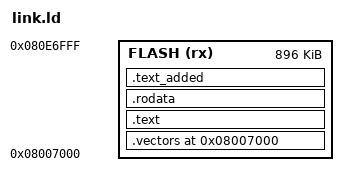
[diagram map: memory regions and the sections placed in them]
/* link.ld - memory layout of the FNIRSI 2C53T application.
 * Below 0x08007000 are the bootloader and the settings / calibration page at 0x08006000; this image
 * starts at 0x08007000 and never covers them.  RAM addresses are absolute in the code
 * (0x20000000..0x20036F8F: initial values 0x20000000..0x2000123F copied from src/ram_init.s at reset, the rest zeroed; stack top 0x20036F90).
 * Layout: vector table at 0x08007000 (the only fixed address), then the original functions in their
 * original order, then the data of src/rodata.s, then code added by this rewrite; each section follows
 * the one before it.  Code and data refer to each other only through symbols, so they may move.  The
 * address comments of the KEEP lines name each unit's address in V1.2.0's layout, not a required one.
 * FLASH ends at APP_END 0x080E7000: above it are the record pages and the bootloader slots of the
 * two-part bootloader (common/layout.inc); the flash is 1024 KB (word 0x00000400 at 0x1FFFF7E0, SYSINFO). */
MEMORY
{
  FLASH (rx) : ORIGIN = 0x08007000, LENGTH = 0x080E7000 - 0x08007000   /* APP_END, common/layout.inc */
}
ENTRY(Reset_Handler)
SECTIONS
{
  .vectors 0x08007000 : { KEEP(*(.vectors)) } > FLASH            /* fixed: the bootloader starts the application here */
  .text :                                                          /* right after the vector table */
  {
    KEEP(*(.text.fn_08007184))                                 /* 0x08007184 */
    KEEP(*(.text.__scatterload))                               /* 0x0800718c */
    KEEP(*(.text.unpack_token_stream))                         /* 0x080071c0 */
    KEEP(*(.text.zero_fill_words))                             /* 0x0800721c */
    KEEP(*(.text.format_one_conversion))                       /* 0x08007238 */
    KEEP(*(.text.fn_080072c8))                                 /* 0x080072c8 */
    KEEP(*(.text.nop_return_080072ec))                         /* 0x080072ec */
    KEEP(*(.text.fn_080072f0))                                 /* 0x080072f0 */
    KEEP(*(.text.fn_08007302))                                 /* 0x08007302 */
    KEEP(*(.text.Reset_Handler))                               /* 0x08007310 */
    KEEP(*(.text.halt_loop_08007332))                          /* 0x08007332 */
    KEEP(*(.text.halt_loop_08007334))                          /* 0x08007334 */
    KEEP(*(.text.halt_loop_08007336))                          /* 0x08007336 */
    KEEP(*(.text.halt_loop_08007338))                          /* 0x08007338 */
    KEEP(*(.text.halt_loop_0800733a))                          /* 0x0800733a */
    KEEP(*(.text.halt_loop_0800733c))                          /* 0x0800733c */
    KEEP(*(.text.halt_loop_0800733e))                          /* 0x0800733e */
    KEEP(*(.text.halt_loop_08007340))                          /* 0x08007340 */
    KEEP(*(.text.halt_loop_08007342))                          /* 0x08007342 */
    KEEP(*(.text.halt_loop_08007344))                          /* 0x08007344 */
    KEEP(*(.text.fn_08007348))                                 /* 0x08007348 */
    KEEP(*(.text.nop_return_0800736c))                         /* 0x0800736c */
    KEEP(*(.text.format_to_buffer_08007370))                   /* 0x08007370 */
    KEEP(*(.text.fn_0800739c))                                 /* 0x0800739c */
    KEEP(*(.text.format_to_buffer_080073b4))                   /* 0x080073b4 */
    KEEP(*(.text.fn_080073e0))                                 /* 0x080073e0 */
    KEEP(*(.text.fn_0800740c))                                 /* 0x0800740c */
    KEEP(*(.text.fn_0800742e))                                 /* 0x0800742e */
    KEEP(*(.text.format_decimal_32))                           /* 0x08007480 */
    KEEP(*(.text.format_hex_u64))                              /* 0x08007520, with format_hex_u32 0x08007576 */
    KEEP(*(.text.fn_080075b4))                                 /* 0x080075b4 */
    KEEP(*(.text.compare_bytes))                               /* 0x0800773c */
    KEEP(*(.text.find_byte))                                   /* 0x08007794 */
    KEEP(*(.text.copy_string_padded))                          /* 0x080077a8 */
    KEEP(*(.text.compare_strings))                             /* 0x08007800 */
    KEEP(*(.text.nop_return_0800787c))                         /* 0x0800787c */
    KEEP(*(.text.nop_return_0800787e))                         /* 0x0800787e */
    KEEP(*(.text.nop_return_08007880))                         /* 0x08007880 */
    KEEP(*(.text.nop_return_08007882))                         /* 0x08007882 */
    KEEP(*(.text.fn_08007884))                                 /* 0x08007884 */
    KEEP(*(.text.fn_0800788e))                                 /* 0x0800788e */
    KEEP(*(.text.fn_0800789a))                                 /* 0x0800789a */
    KEEP(*(.text.fn_080078ac))                                 /* 0x080078ac */
    KEEP(*(.text.emit_formatted_number))                       /* 0x080078be */
    KEEP(*(.text.fn_08007970))                                 /* 0x08007970 */
    KEEP(*(.text.fn_08007a10))                                 /* 0x08007a10 */
    KEEP(*(.text.format_float_efg))                            /* 0x08007b20 */
    KEEP(*(.text.format_float_hex))                            /* 0x08007d8c */
    KEEP(*(.text.read_byte_advance))                           /* 0x08008088, with fn_08008092 0x08008092 */
    KEEP(*(.text.store_byte_advance))                          /* 0x080080b8 */
    KEEP(*(.text.emit_text_conversion))                        /* 0x080080c2 */
    KEEP(*(.text.fn_080080f0))                                 /* 0x080080f0 */
    KEEP(*(.text.fn_08008114))                                 /* 0x08008114 */
    KEEP(*(.text.format_decimal_64))                           /* 0x080081d0 */
    KEEP(*(.text.format_octal_64))                             /* 0x0800824c, with format_octal_32 0x08008290 */
    KEEP(*(.text.zero_bytes))                                  /* 0x080082bc */
    KEEP(*(.text.fill_bytes_body))                             /* 0x080082c0 */
    KEEP(*(.text.fn_08008300))                                 /* 0x08008300 */
    KEEP(*(.text.fn_08008308))                                 /* 0x08008308 */
    KEEP(*(.text.div10_u64))                                   /* 0x08008310 */
    KEEP(*(.text.fn_0800839c))                                 /* 0x0800839c */
    KEEP(*(.text.emit_text_conversion_wide))                   /* 0x0800841c */
    KEEP(*(.text.fn_08008448))                                 /* 0x08008448 */
    KEEP(*(.text.fn_0800852c))                                 /* 0x0800852c */
    KEEP(*(.text.fn_08008534))                                 /* 0x08008534 */
    KEEP(*(.text.zero_bytes_aligned))                          /* 0x0800857c */
    KEEP(*(.text.fill_bytes_aligned_body))                     /* 0x08008580 */
    KEEP(*(.text.fn_080085cc))                                 /* 0x080085cc */
    KEEP(*(.text.fn_080085d4))                                 /* 0x080085d4 */
    KEEP(*(.text.fn_08008620))                                 /* 0x08008620 */
    KEEP(*(.text.fn_08008630))                                 /* 0x08008630 */
    KEEP(*(.text.divide_u64))                                  /* 0x08008642 */
    KEEP(*(.text.divide_u64_by_zero_result))                   /* 0x0800871c */
    KEEP(*(.text.divide_s64))                                  /* 0x08008732 */
    KEEP(*(.text.divide_s64_by_zero_result))                   /* 0x08008780 */
    KEEP(*(.text.copy_bytes_forward))                          /* 0x080087a6 */
    KEEP(*(.text.fill_bytes))                                  /* 0x08008830 */
    KEEP(*(.text.copy_bytes_aligned_body))                     /* 0x08008840 */
    KEEP(*(.text.fn_080088a4))                                 /* 0x080088a4 */
    KEEP(*(.text.fn_08008a58))                                 /* 0x08008a58 */
    KEEP(*(.text.fn_08008c60))                                 /* 0x08008c60 */
    KEEP(*(.text.halt_loop_080092d8))                          /* 0x080092d8 */
    KEEP(*(.text.fn_080092dc))                                 /* 0x080092dc */
    KEEP(*(.text.fn_08009670))                                 /* 0x08009670 */
    KEEP(*(.text.nop_return_080097e4))                         /* 0x080097e4 */
    KEEP(*(.text.fn_080097e8))                                 /* 0x080097e8 */
    KEEP(*(.text.fn_080098e0))                                 /* 0x080098e0 */
    KEEP(*(.text.fn_08009c10))                                 /* 0x08009c10 */
    KEEP(*(.text.fn_08009c78))                                 /* 0x08009c78 */
    KEEP(*(.text.fn_08009fe0))                                 /* 0x08009fe0 */
    KEEP(*(.text.fn_08009fe8))                                 /* 0x08009fe8 */
    KEEP(*(.text.fn_0800a148))                                 /* 0x0800a148 */
    KEEP(*(.text.fn_0800a900))                                 /* 0x0800a900 */
    KEEP(*(.text.fn_0800b1f8))                                 /* 0x0800b1f8 */
    KEEP(*(.text.fn_0800b7cc))                                 /* 0x0800b7cc */
    KEEP(*(.text.fn_0800bd60))                                 /* 0x0800bd60 */
    KEEP(*(.text.fn_0800cb50))                                 /* 0x0800cb50 */
    KEEP(*(.text.fn_0800cfcc))                                 /* 0x0800cfcc */
    KEEP(*(.text.fn_0800d120))                                 /* 0x0800d120 */
    KEEP(*(.text.fn_0800d2f8))                                 /* 0x0800d2f8 */
    KEEP(*(.text.fn_0800d418))                                 /* 0x0800d418 */
    KEEP(*(.text.fn_0800d548))                                 /* 0x0800d548 */
    KEEP(*(.text.fn_0800d6ac))                                 /* 0x0800d6ac */
    KEEP(*(.text.fn_0800d7e4))                                 /* 0x0800d7e4 */
    KEEP(*(.text.fn_0800d834))                                 /* 0x0800d834 */
    KEEP(*(.text.fn_0800d954))                                 /* 0x0800d954 */
    KEEP(*(.text.fn_0800df58))                                 /* 0x0800df58 */
    KEEP(*(.text.fn_0800e2f4))                                 /* 0x0800e2f4 */
    KEEP(*(.text.fn_0800e3e4))                                 /* 0x0800e3e4 */
    KEEP(*(.text.fn_0800e4f4))                                 /* 0x0800e4f4 */
    KEEP(*(.text.fn_0800e60c))                                 /* 0x0800e60c */
    KEEP(*(.text.fn_0800e630))                                 /* 0x0800e630 */
    KEEP(*(.text.draw_text_column_with_char_highlight))        /* 0x0800e64c */
    KEEP(*(.text.draw_wrapped_text_in_box))                    /* 0x0800f154 */
    KEEP(*(.text.blend_glyph_into_region_buffer))              /* 0x0800fb90 */
    KEEP(*(.text.halt_loop_0800fd34))                          /* 0x0800fd34 */
    KEEP(*(.text.fn_0800fd38))                                 /* 0x0800fd38 */
    KEEP(*(.text.fn_0800fe9c))                                 /* 0x0800fe9c */
    KEEP(*(.text.fn_0800fef0))                                 /* 0x0800fef0 */
    KEEP(*(.text.fn_0800ffb8))                                 /* 0x0800ffb8 */
    KEEP(*(.text.fn_08010014))                                 /* 0x08010014 */
    KEEP(*(.text.fn_08010158))                                 /* 0x08010158 */
    KEEP(*(.text.fn_080101ac))                                 /* 0x080101ac */
    KEEP(*(.text.fn_08010200))                                 /* 0x08010200 */
    KEEP(*(.text.fn_0801025c))                                 /* 0x0801025c */
    KEEP(*(.text.fn_080102b8))                                 /* 0x080102b8 */
    KEEP(*(.text.fn_08010314))                                 /* 0x08010314 */
    KEEP(*(.text.fn_080103f4))                                 /* 0x080103f4 */
    KEEP(*(.text.fn_080104ec))                                 /* 0x080104ec */
    KEEP(*(.text.fn_08010584))                                 /* 0x08010584 */
    KEEP(*(.text.fn_0801067c))                                 /* 0x0801067c */
    KEEP(*(.text.fn_080106e8))                                 /* 0x080106e8 */
    KEEP(*(.text.fn_080107c8))                                 /* 0x080107c8 */
    KEEP(*(.text.fn_080108c0))                                 /* 0x080108c0 */
    KEEP(*(.text.fn_08010924))                                 /* 0x08010924 */
    KEEP(*(.text.fn_08010a1c))                                 /* 0x08010a1c */
    KEEP(*(.text.fn_08010a94))                                 /* 0x08010a94 */
    KEEP(*(.text.fn_08010b80))                                 /* 0x08010b80 */
    KEEP(*(.text.fn_08010c78))                                 /* 0x08010c78 */
    KEEP(*(.text.fn_08010d70))                                 /* 0x08010d70 */
    KEEP(*(.text.fn_08010e70))                                 /* 0x08010e70 */
    KEEP(*(.text.fn_08010f68))                                 /* 0x08010f68 */
    KEEP(*(.text.fn_08011048))                                 /* 0x08011048 */
    KEEP(*(.text.fn_08011140))                                 /* 0x08011140 */
    KEEP(*(.text.fn_08011238))                                 /* 0x08011238 */
    KEEP(*(.text.fn_080114c4))                                 /* 0x080114c4 */
    KEEP(*(.text.fn_08011660))                                 /* 0x08011660 */
    KEEP(*(.text.fn_080116ec))                                 /* 0x080116ec */
    KEEP(*(.text.fn_080117cc))                                 /* 0x080117cc */
    KEEP(*(.text.fn_08011828))                                 /* 0x08011828 */
    KEEP(*(.text.fn_08011b74))                                 /* 0x08011b74 */
    KEEP(*(.text.fn_08011c10))                                 /* 0x08011c10 */
    KEEP(*(.text.fn_08011d08))                                 /* 0x08011d08 */
    KEEP(*(.text.fn_08011dfc))                                 /* 0x08011dfc */
    KEEP(*(.text.fn_08011e84))                                 /* 0x08011e84 */
    KEEP(*(.text.fn_0801215c))                                 /* 0x0801215c */
    KEEP(*(.text.fn_08012244))                                 /* 0x08012244 */
    KEEP(*(.text.fn_08012344))                                 /* 0x08012344 */
    KEEP(*(.text.fn_08012478))                                 /* 0x08012478 */
    KEEP(*(.text.fn_08012778))                                 /* 0x08012778 */
    KEEP(*(.text.fn_08012844))                                 /* 0x08012844 */
    KEEP(*(.text.send_state_message_sequence))                 /* 0x08012908 */
    KEEP(*(.text.jump_indirect_through_table))                 /* 0x08012cd4 */
    KEEP(*(.text.fn_08012ce8))                                 /* 0x08012ce8 */
    KEEP(*(.text.fn_08012d2c))                                 /* 0x08012d2c */
    KEEP(*(.text.fn_08012d84))                                 /* 0x08012d84 */
    KEEP(*(.text.fn_08012de0))                                 /* 0x08012de0 */
    KEEP(*(.text.fn_08012ff4))                                 /* 0x08012ff4 */
    KEEP(*(.text.draw_panels_by_selector_20001062))            /* 0x08013338 */
    KEEP(*(.text.fn_08015740))                                 /* 0x08015740 */
    KEEP(*(.text.draw_six_row_list_from_first_index))          /* 0x0801579c */
    KEEP(*(.text.draw_three_value_rows))                       /* 0x08015988 */
    KEEP(*(.text.draw_header_image_120))                       /* 0x08015c08 */
    KEEP(*(.text.draw_arc_gauge))                              /* 0x08015c70 */
    KEEP(*(.text.draw_seven_icon_row))                         /* 0x080163f8 */
    KEEP(*(.text.draw_waveform_display))                       /* 0x080165a8 */
    KEEP(*(.text.draw_value_panel))                            /* 0x0801cab0 */
    KEEP(*(.text.fn_0801ccfc))                                 /* 0x0801ccfc */
    KEEP(*(.text.draw_six_row_list))                           /* 0x0801cd58 */
    KEEP(*(.text.draw_page_by_selector_nibble))                /* 0x0801cf50 */
    KEEP(*(.text.draw_image_two_texts_and_s_value))            /* 0x0801e458 */
    KEEP(*(.text.fn_0801e514))                                 /* 0x0801e514 */
    KEEP(*(.text.draw_page_position_bar))                      /* 0x0801e570 */
    KEEP(*(.text.draw_bottom_strip))                           /* 0x0801e784 */
    KEEP(*(.text.draw_thumbnail_grid))                         /* 0x0801ede8 */
    KEEP(*(.text.draw_image_and_three_texts))                  /* 0x0801f19c */
    KEEP(*(.text.draw_bitmap_and_text))                        /* 0x0801f2c4 */
    KEEP(*(.text.draw_language_list))                          /* 0x0801f324 */
    KEEP(*(.text.draw_channel_offset_markers_0801f608))        /* 0x0801f608 */
    KEEP(*(.text.fn_0801f60c))                                 /* 0x0801f60c */
    KEEP(*(.text.draw_percent_bar))                            /* 0x0801f660 */
    KEEP(*(.text.fn_0801f8e0))                                 /* 0x0801f8e0 */
    KEEP(*(.text.fn_0801f924))                                 /* 0x0801f924 */
    KEEP(*(.text.return_void_2))                               /* 0x0801f960 */
    KEEP(*(.text.blend_subpixel_point))                        /* 0x0801f964 */
    KEEP(*(.text.draw_arc_degrees))                            /* 0x0801faf0 */
    KEEP(*(.text.blend_pixel_rgb565))                          /* 0x0801fcb0 */
    KEEP(*(.text.draw_line))                                   /* 0x0801fda0 */
    KEEP(*(.text.fn_0801fea8))                                 /* 0x0801fea8 */
    KEEP(*(.text.draw_4bpp_bitmap))                            /* 0x0801ffcc */
    KEEP(*(.text.draw_gradient_bar))                           /* 0x08020134 */
    KEEP(*(.text.halve_rect_rgb565))                           /* 0x08020330 */
    KEEP(*(.text.draw_circle_octants))                         /* 0x08020470 */
    KEEP(*(.text.fill_triangle))                               /* 0x08020af8 */
    KEEP(*(.text.draw_rounded_rect_outline))                   /* 0x08020c48 */
    KEEP(*(.text.recolor_rect_above_threshold))                /* 0x08020ce8 */
    KEEP(*(.text.read_halfword_60020000))                      /* 0x08020e00 */
    KEEP(*(.text.write_window_xy_60020000))                    /* 0x08020e18 */
    KEEP(*(.text.write_halfword_60020000))                     /* 0x08020e6c */
    KEEP(*(.text.write_halfword_6001fffe_from_20008348))       /* 0x08020e78 */
    KEEP(*(.text.halt_forever_08020e90))                       /* 0x08020e90 */
    KEEP(*(.text.return_void))                                 /* 0x08020e94 */
    KEEP(*(.text.fn_08020e98))                                 /* 0x08020e98 */
    KEEP(*(.text.fn_080242ec))                                 /* 0x080242ec */
    KEEP(*(.text.compute_spectrum_bytes))                      /* 0x080251e4 */
    KEEP(*(.text.fn_08025aac))                                 /* 0x08025aac */
    KEEP(*(.text.fn_08025fc0))                                 /* 0x08025fc0 */
    KEEP(*(.text.compute_channel_measurements))                /* 0x080266f8 */
    KEEP(*(.text.compute_math_trace))                          /* 0x08027930 */
    KEEP(*(.text.draw_channel_offset_markers_08028b40))        /* 0x08028b40 */
    KEEP(*(.text.psp_context_save_restore))                    /* 0x08028d50 */
    KEEP(*(.text.svc_restore_context))                         /* 0x08028dc0 */
    KEEP(*(.text.find_level_crossing))                         /* 0x08028de4 */
    KEEP(*(.text.save_settings_to_flash))                      /* 0x080293bc */
    KEEP(*(.text.fn_08029d40))                                 /* 0x08029d40 */
    KEEP(*(.text.fill_output_waveform_table))                  /* 0x08029e14 */
    KEEP(*(.text.systick_handler))                             /* 0x0802a994 */
    KEEP(*(.text.fn_0802a9c4))                                 /* 0x0802a9c4 */
    KEEP(*(.text.system_bring_up))                             /* 0x0802aa50 */
    KEEP(*(.text.fn_0802e71c))                                 /* 0x0802e71c */
    KEEP(*(.text.fn_0802e78c))                                 /* 0x0802e78c */
    KEEP(*(.text.fn_0802e7b4))                                 /* 0x0802e7b4 */
    KEEP(*(.text.usb_device_event_handler))                    /* 0x0802e8e4 */
    KEEP(*(.text.halt_forever_0802f310))                       /* 0x0802f310 */
    KEEP(*(.text.system_reset))                                /* 0x0802f314 */
    KEEP(*(.text.lookup_sorted_table_ptr_0802f340))            /* 0x0802f340 */
    KEEP(*(.text.lookup_sorted_table_ptr_0802f3b4))            /* 0x0802f3b4 */
    KEEP(*(.text.lookup_sorted_table_ptr_0802f428))            /* 0x0802f428 */
    KEEP(*(.text.lookup_sorted_table_ptr_0802f49c))            /* 0x0802f49c */
    KEEP(*(.text.lookup_sorted_table_ptr_0802f510))            /* 0x0802f510 */
    KEEP(*(.text.lookup_sorted_table_ptr_0802f584))            /* 0x0802f584 */
    KEEP(*(.text.lookup_sorted_table_ptr_0802f5f8))            /* 0x0802f5f8 */
    KEEP(*(.text.lookup_sorted_table_ptr_0802f66c))            /* 0x0802f66c */
    KEEP(*(.text.lookup_sorted_table_fields_0802f6e0))         /* 0x0802f6e0 */
    KEEP(*(.text.lookup_sorted_table_fields_0802f774))         /* 0x0802f774 */
    KEEP(*(.text.lookup_sorted_table_fields_0802f808))         /* 0x0802f808 */
    KEEP(*(.text.lookup_sorted_table_fields_0802f89c))         /* 0x0802f89c */
    KEEP(*(.text.lookup_sorted_table_fields_0802f930))         /* 0x0802f930 */
    KEEP(*(.text.lookup_sorted_table_fields_0802f9c4))         /* 0x0802f9c4 */
    KEEP(*(.text.lookup_sorted_table_fields_0802fa58))         /* 0x0802fa58 */
    KEEP(*(.text.lookup_sorted_table_fields_0802faec))         /* 0x0802faec */
    KEEP(*(.text.fft64_radix8_in_place))                       /* 0x0802fb80 */
    KEEP(*(.text.parse_signed_decimal))                        /* 0x0803012c */
    KEEP(*(.text.scsi_command_dispatch))                       /* 0x0803020c */
    KEEP(*(.text.sort_bytes_ascending))                        /* 0x0803085c */
    KEEP(*(.text.polar_degrees_to_xy_center_160_225))          /* 0x080308c0 */
    KEEP(*(.text.fn_08030a70))                                 /* 0x08030a70 */
    KEEP(*(.text.validate_boot_sector))                        /* 0x08030b80 */
    KEEP(*(.text.fn_08030ca0))                                 /* 0x08030ca0 */
    KEEP(*(.text.return_zero_08030cb8))                        /* 0x08030cb8 */
    KEEP(*(.text.return_zero_08030cbc))                        /* 0x08030cbc */
    KEEP(*(.text.return_zero_08030cc0))                        /* 0x08030cc0 */
    KEEP(*(.text.send_status_block_after_data))                /* 0x08030cc4 */
    KEEP(*(.text.init_state_arm_command_receive))              /* 0x08030da0 */
    KEEP(*(.text.handle_command_block_or_write_data))          /* 0x08030e0c */
    KEEP(*(.text.msc_control_request_handler))                 /* 0x08031078 */
    KEEP(*(.text.return_zero_080312d0))                        /* 0x080312d0 */
    KEEP(*(.text.next_or_allocate_cluster))                    /* 0x080312d4 */
    KEEP(*(.text.compute_clock_frequencies))                   /* 0x08031430 */
    KEEP(*(.text.set_bit_in_register))                         /* 0x08031514 */
    KEEP(*(.text.show_bmp_file_fullscreen))                    /* 0x08031534 */
    KEEP(*(.text.find_directory_entry_by_name))                /* 0x08031664 */
    KEEP(*(.text.dir_read_next_entry_with_long_name))          /* 0x08032de4 */
    KEEP(*(.text.dir_add_entry))                               /* 0x08033250 */
    KEEP(*(.text.dir_set_offset))                              /* 0x08033e94 */
    KEEP(*(.text.write_sector_run))                            /* 0x08033f38 */
    KEEP(*(.text.fn_08033f7c))                                 /* 0x08033f7c */
    KEEP(*(.text.fn_08033fbc))                                 /* 0x08033fbc */
    KEEP(*(.text.file_close))                                  /* 0x08034014 */
    KEEP(*(.text.object_release))                              /* 0x080341c4 */
    KEEP(*(.text.file_seek))                                   /* 0x080341e8 */
    KEEP(*(.text.dir_create))                                  /* 0x08034534 */
    KEEP(*(.text.drive_unmount))                               /* 0x08034774 */
    KEEP(*(.text.drive_mount))                                 /* 0x0803480c */
    KEEP(*(.text.file_open))                                   /* 0x080348b8 */
    KEEP(*(.text.dir_open))                                    /* 0x08034c40 */
    KEEP(*(.text.file_read))                                   /* 0x08034cbc */
    KEEP(*(.text.dir_read_entry))                              /* 0x08034f20 */
    KEEP(*(.text.path_delete))                                 /* 0x0803512c */
    KEEP(*(.text.file_write))                                  /* 0x08035530 */
    KEEP(*(.text.filesystem_startup_setup))                    /* 0x080357bc */
    KEEP(*(.text.character_code_to_byte))                      /* 0x08035908 */
    KEEP(*(.text.screenshot_file_find_name))                   /* 0x08035a08 */
    KEEP(*(.text.flash_program_halfword))                      /* 0x08035afc */
    KEEP(*(.text.serial_device_command_20_with_address))       /* 0x08035e9c */
    KEEP(*(.text.serial_device_command_90_clock_two_bytes))    /* 0x08035ee8 */
    KEEP(*(.text.serial_device_interface_init))                /* 0x08035f48 */
    KEEP(*(.text.serial_device_read))                          /* 0x08036048 */
    KEEP(*(.text.serial_device_clock_byte))                    /* 0x080360b8 */
    KEEP(*(.text.serial_device_transfer_byte))                 /* 0x080360c4 */
    KEEP(*(.text.serial_device_wait_status_bit0_clear))        /* 0x0803611c */
    KEEP(*(.text.serial_device_write_merge))                   /* 0x0803616c */
    KEEP(*(.text.serial_device_write_chunks))                  /* 0x080362ac */
    KEEP(*(.text.serial_device_send_command_6))                /* 0x08036344 */
    KEEP(*(.text.serial_device_write_bytes))                   /* 0x0803636c */
    KEEP(*(.text.fn_080363e4))                                 /* 0x080363e4 */
    KEEP(*(.text.fn_080365ec))                                 /* 0x080365ec */
    KEEP(*(.text.path_resolve))                                /* 0x080366d8 */
    KEEP(*(.text.fn_08036ba4))                                 /* 0x08036ba4 */
    KEEP(*(.text.set_string_descriptor_mass_storage_config))   /* 0x08036bd0 */
    KEEP(*(.text.get_configuration_descriptor_record))         /* 0x08036c4c */
    KEEP(*(.text.get_device_descriptor_record))                /* 0x08036c58 */
    KEEP(*(.text.set_string_descriptor_mass_storage_interface)) /* 0x08036c64 */
    KEEP(*(.text.get_language_id_descriptor_record))           /* 0x08036cf0 */
    KEEP(*(.text.fn_08036cfc))                                 /* 0x08036cfc */
    KEEP(*(.text.fn_08036d38))                                 /* 0x08036d38 */
    KEEP(*(.text.fn_08036d3c))                                 /* 0x08036d3c */
    KEEP(*(.text.fn_08036db0))                                 /* 0x08036db0 */
    KEEP(*(.text.build_hex_id_string_descriptor_record))       /* 0x08036db4 */
    KEEP(*(.text.allocation_table_read))                       /* 0x08036f18 */
    KEEP(*(.text.set_nibble_fields_from_bit_mask))             /* 0x080372fc */
    KEEP(*(.text.all_bits_set))                                /* 0x080374e0 */
    KEEP(*(.text.file_read_or_skip_bytes))                     /* 0x080374f0 */
    KEEP(*(.text.decode_scan_data_to_rgb565))                  /* 0x08037524 */
    KEEP(*(.text.parse_jpeg_header))                           /* 0x08038f20 */
    KEEP(*(.text.decode_image_file_with_offset))               /* 0x08039f6c */
    KEEP(*(.text.copy_rect_into_clip_buffer))                  /* 0x0803a174 */
    KEEP(*(.text.write_pixel_window_to_port))                  /* 0x0803a23c */
    KEEP(*(.text.read_numbered_bin_file))                      /* 0x0803a310 */
    KEEP(*(.text.decode_utf8_char))                            /* 0x0803a40c */
    KEEP(*(.text.init_system_clock))                           /* 0x0803a4ec */
    KEEP(*(.text.mount_fat_volume))                            /* 0x0803a7a0 */
    KEEP(*(.text.init_alloc_table))                            /* 0x0803ab10 */
    KEEP(*(.text.alloc_table_used_permille))                   /* 0x0803ab34 */
    KEEP(*(.text.fill_halfwords))                              /* 0x0803ac6c */
    KEEP(*(.text.free_units_of_32_bytes))                      /* 0x0803acbc */
    KEEP(*(.text.alloc_units_of_32_bytes))                     /* 0x0803acfc */
    KEEP(*(.text.map_masked_byte_to_code))                     /* 0x0803aef8 */
    KEEP(*(.text.reset_system))                                /* 0x0803b070 */
    KEEP(*(.text.fn_0803b078))                                 /* 0x0803b078 */
    KEEP(*(.text.fn_0803b2f8))                                 /* 0x0803b2f8 */
    KEEP(*(.text.image_rect_callback))                         /* 0x0803b828 */
    KEEP(*(.text.scan_capture_files))                          /* 0x0803b878 */
    KEEP(*(.text.task_delay_current))                          /* 0x0803b9b8 */
    KEEP(*(.text.task_register_ready))                         /* 0x0803bab0 */
    KEEP(*(.text.timer_service_init))                          /* 0x0803bbc0 */
    KEEP(*(.text.free_terminated_tasks))                       /* 0x0803bc24 */
    KEEP(*(.text.queue_copy_out_item))                         /* 0x0803bc80 */
    KEEP(*(.text.queue_copy_in_item))                          /* 0x0803bcc4 */
    KEEP(*(.text.free_task_memory))                            /* 0x0803bd90 */
    KEEP(*(.text.waiting_list_top_priority))                   /* 0x0803bda8 */
    KEEP(*(.text.timer_list_next_expiry))                      /* 0x0803bdd0 */
    KEEP(*(.text.heap_init_free_list))                         /* 0x0803be10 */
    KEEP(*(.text.idle_task_loop))                              /* 0x0803becc */
    KEEP(*(.text.queue_init_fields))                           /* 0x0803bf04 */
    KEEP(*(.text.task_init_record))                            /* 0x0803bf44 */
    KEEP(*(.text.timer_init_record))                           /* 0x0803c058 */
    KEEP(*(.text.task_lists_init))                             /* 0x0803c0d0 */
    KEEP(*(.text.heap_insert_free_block))                      /* 0x0803c15c */
    KEEP(*(.text.timer_insert_active))                         /* 0x0803c224 */
    KEEP(*(.text.queue_is_empty))                              /* 0x0803c2ac */
    KEEP(*(.text.queue_is_full))                               /* 0x0803c2d4 */
    KEEP(*(.text.reset_msp_and_call_svc0))                     /* 0x0803c304 */
    KEEP(*(.text.timer_expire_first))                          /* 0x0803c32c */
    KEEP(*(.text.timer_process_commands))                      /* 0x0803c3b4 */
    KEEP(*(.text.timer_service_step))                          /* 0x0803c504 */
    KEEP(*(.text.update_next_unblock_time))                    /* 0x0803c5a0 */
    KEEP(*(.text.timer_get_time_detect_wrap))                  /* 0x0803c5dc */
    KEEP(*(.text.timer_process_wrap))                          /* 0x0803c620 */
    KEEP(*(.text.task_return_trap))                            /* 0x0803c6f0 */
    KEEP(*(.text.task_is_suspended))                           /* 0x0803c730 */
    KEEP(*(.text.timer_service_task))                          /* 0x0803c79c */
    KEEP(*(.text.queue_unlock))                                /* 0x0803c7b8 */
    KEEP(*(.text.fat_set_entry))                               /* 0x0803c86c */
    KEEP(*(.text.heap_alloc_first_fit))                        /* 0x0803cc64 */
    KEEP(*(.text.current_task_increment_field_0x48))           /* 0x0803ce80 */
    KEEP(*(.text.task_stack_init_frame))                       /* 0x0803ceac */
    KEEP(*(.text.write_numbered_bin_file))                     /* 0x0803ced4 */
    KEEP(*(.text.save_screen_bmp))                             /* 0x0803d084 */
    KEEP(*(.text.fir_filter_rows))                             /* 0x0803d5d4 */
    KEEP(*(.text.fn_0803d820))                                 /* 0x0803d820 */
    KEEP(*(.text.set_bit6))                                    /* 0x0803d830 */
    KEEP(*(.text.word8_any_bit_set))                           /* 0x0803d83c */
    KEEP(*(.text.fn_0803d848))                                 /* 0x0803d848 */
    KEEP(*(.text.fat_sync_volume))                             /* 0x0803d934 */
    KEEP(*(.text.fn_0803da50))                                 /* 0x0803da50 */
    KEEP(*(.text.fn_0803dac0))                                 /* 0x0803dac0 */
    KEEP(*(.text.fn_0803e3f4))                                 /* 0x0803e3f4 */
    KEEP(*(.text.fn_0803e454))                                 /* 0x0803e454 */
    KEEP(*(.text.fn_08040008))                                 /* 0x08040008 */
    KEEP(*(.text.fn_0804009c))                                 /* 0x0804009c */
    KEEP(*(.text.fn_080400b8))                                 /* 0x080400b8 */
    KEEP(*(.text.fn_080406c8))                                 /* 0x080406c8 */
    KEEP(*(.text.fn_08040734))                                 /* 0x08040734 */
    KEEP(*(.text.fn_08040874))                                 /* 0x08040874 */
    KEEP(*(.text.fn_08040990))                                 /* 0x08040990 */
    KEEP(*(.text.fn_08040b24))                                 /* 0x08040b24 */
    KEEP(*(.text.fn_08040eb4))                                 /* 0x08040eb4 */
    KEEP(*(.text.list_unlink_node))                            /* 0x08041024 */
    KEEP(*(.text.list_init))                                   /* 0x0804106c */
    KEEP(*(.text.fn_0804109c))                                 /* 0x0804109c */
    KEEP(*(.text.list_insert_sorted))                          /* 0x080410ac */
    KEEP(*(.text.list_insert_before_cursor))                   /* 0x08041118 */
    KEEP(*(.text.enable_fpu_access))                           /* 0x08041154 */
    KEEP(*(.text.enter_critical))                              /* 0x08041168 */
    KEEP(*(.text.exit_critical))                               /* 0x080411b0 */
    KEEP(*(.text.heap_free))                                   /* 0x080411e0 */
    KEEP(*(.text.check_irq_priority_limits))                   /* 0x080412c8 */
    KEEP(*(.text.fn_0804132c))                                 /* 0x0804132c */
    KEEP(*(.text.fn_08041390))                                 /* 0x08041390 */
    KEEP(*(.text.fn_08041400))                                 /* 0x08041400 */
    KEEP(*(.text.set_flag_200061e8))                           /* 0x08041424 */
    KEEP(*(.text.fn_08041434))                                 /* 0x08041434 */
    KEEP(*(.text.fn_08041478))                                 /* 0x08041478 */
    KEEP(*(.text.fn_080414cc))                                 /* 0x080414cc */
    KEEP(*(.text.fn_08041610))                                 /* 0x08041610 */
    KEEP(*(.text.create_idle_and_tmr_svc_tasks))               /* 0x080416d8 */
    KEEP(*(.text.fn_0804178c))                                 /* 0x0804178c */
    KEEP(*(.text.increment_word_200061e4))                     /* 0x08041904 */
    KEEP(*(.text.fn_08041914))                                 /* 0x08041914 */
    KEEP(*(.text.fn_080419d4))                                 /* 0x080419d4 */
    KEEP(*(.text.fn_08041b74))                                 /* 0x08041b74 */
    KEEP(*(.text.queue_reset))                                 /* 0x08041c38 */
    KEEP(*(.text.queue_send_timeout))                          /* 0x08041cf0 */
    KEEP(*(.text.queue_send_from_isr))                         /* 0x08041f08 */
    KEEP(*(.text.fn_0804206c))                                 /* 0x0804206c */
    KEEP(*(.text.semaphore_give_from_isr))                     /* 0x0804209c */
    KEEP(*(.text.queue_receive_timeout))                       /* 0x080421d8 */
    KEEP(*(.text.semaphore_take_timeout))                      /* 0x080423a8 */
    KEEP(*(.text.fn_080425cc))                                 /* 0x080425cc */
    KEEP(*(.text.fn_080426a0))                                 /* 0x080426a0 */
    KEEP(*(.text.fn_08042730))                                 /* 0x08042730 */
    KEEP(*(.text.get_word_200062d4))                           /* 0x08042768 */
    KEEP(*(.text.fn_0804277c))                                 /* 0x0804277c */
    KEEP(*(.text.fn_08042934))                                 /* 0x08042934 */
    KEEP(*(.text.fn_08042a2c))                                 /* 0x08042a2c */
    KEEP(*(.text.fn_08042b4c))                                 /* 0x08042b4c */
    KEEP(*(.text.fn_08042c10))                                 /* 0x08042c10 */
    KEEP(*(.text.fn_08042d88))                                 /* 0x08042d88 */
    KEEP(*(.text.create_tmr_svc_record_or_halt))               /* 0x08042dd4 */
    KEEP(*(.text.fn_08042e38))                                 /* 0x08042e38 */
    KEEP(*(.text.fn_08042ee0))                                 /* 0x08042ee0 */
    KEEP(*(.text.fn_08043046))                                 /* 0x08043046 */
    KEEP(*(.text.fn_0804312c))                                 /* 0x0804312c */
    KEEP(*(.text.fn_08043464))                                 /* 0x08043464 */
    KEEP(*(.text.fn_08043540))                                 /* 0x08043540 */
    KEEP(*(.text.fn_0804356a))                                 /* 0x0804356a */
    KEEP(*(.text.fn_08043594))                                 /* 0x08043594 */
    KEEP(*(.text.classify_double))                             /* 0x080437d8 */
    KEEP(*(.text.classify_float))                              /* 0x08043808 */
    KEEP(*(.text.float_remainder_sign_fixup))                  /* 0x0804382e */
    KEEP(*(.text.double_pow))                                  /* 0x080438e0 */
    KEEP(*(.text.float_pow))                                   /* 0x08044540 */
    KEEP(*(.text.double_sqrt_checked))                         /* 0x08044ba4 */
    KEEP(*(.text.sqrt_f32_checked))                            /* 0x08044c1e */
    KEEP(*(.text.double_poly_eval))                            /* 0x08044c58 */
    KEEP(*(.text.fn_08044d50))                                 /* 0x08044d50 */
    KEEP(*(.text.double_add_vfp_regs))                         /* 0x08044d80 */
    KEEP(*(.text.fn_08044db8))                                 /* 0x08044db8 */
    KEEP(*(.text.fn_08044dd8))                                 /* 0x08044dd8 */
    KEEP(*(.text.fn_08044df8))                                 /* 0x08044df8 */
    KEEP(*(.text.float_return_nan))                            /* 0x08044e14 */
    KEEP(*(.text.fn_08044e24))                                 /* 0x08044e24 */
    KEEP(*(.text.fn_08044e34))                                 /* 0x08044e34 */
    KEEP(*(.text.is_ascii_digit))                              /* 0x08044e44 */
    KEEP(*(.text.abs_f64_08044e52))                            /* 0x08044e52 */
    KEEP(*(.text.double_sqrt_checked_08044e6a))                /* 0x08044e6a */
    KEEP(*(.text.fn_08044ed8))                                 /* 0x08044ed8 */
    KEEP(*(.text.fn_08044f04))                                 /* 0x08044f04 */
    KEEP(*(.text.negate_f64))                                  /* 0x08044f30 */
    KEEP(*(.text.negate_f32))                                  /* 0x08044f36 */
    KEEP(*(.text.abs_f64_08044f3c))                            /* 0x08044f3c */
    KEEP(*(.text.abs_f32))                                     /* 0x08044f42 */
    KEEP(*(.text.double_to_float))                             /* 0x08044f48 */
    KEEP(*(.text.double_to_float_special_case))                /* 0x08044f92 */
    KEEP(*(.text.double_add))                                  /* 0x08044fac */
    KEEP(*(.text.double_add_same_sign))                        /* 0x08044fbc */
    KEEP(*(.text.fn_08045042))                                 /* 0x08045042 */
    KEEP(*(.text.fn_0804504e))                                 /* 0x0804504e */
    KEEP(*(.text.fn_080450ae))                                 /* 0x080450ae */
    KEEP(*(.text.fn_0804510c))                                 /* 0x0804510c */
    KEEP(*(.text.double_div))                                  /* 0x08045124 */
    KEEP(*(.text.fn_080453d8))                                 /* 0x080453d8 */
    KEEP(*(.text.fn_0804543a))                                 /* 0x0804543a */
    KEEP(*(.text.double_to_i32))                               /* 0x08045450 */
    KEEP(*(.text.double_to_i32_special_case))                  /* 0x0804549e */
    KEEP(*(.text.double_to_u32))                               /* 0x080454b0 */
    KEEP(*(.text.double_to_u32_special_case))                  /* 0x080454f8 */
    KEEP(*(.text.i32_to_double))                               /* 0x0804550a */
    KEEP(*(.text.i64_to_double))                               /* 0x08045538 */
    KEEP(*(.text.u32_to_double))                               /* 0x080455da */
    KEEP(*(.text.u64_to_double))                               /* 0x08045600 */
    KEEP(*(.text.fn_0804568c))                                 /* 0x0804568c */
    KEEP(*(.text.double_compare_special_case))                 /* 0x080456ee */
    KEEP(*(.text.fn_08045704))                                 /* 0x08045704 */
    KEEP(*(.text.fn_08045766))                                 /* 0x08045766 */
    KEEP(*(.text.double_mul))                                  /* 0x0804577c */
    KEEP(*(.text.double_special_dispatch))                     /* 0x080458d0 */
    KEEP(*(.text.double_return_infinity))                      /* 0x0804596c */
    KEEP(*(.text.fn_08045978))                                 /* 0x08045978 */
    KEEP(*(.text.double_rsub))                                 /* 0x080459e4 */
    KEEP(*(.text.double_sqrt))                                 /* 0x080459fc */
    KEEP(*(.text.double_sub))                                  /* 0x08045b94 */
    KEEP(*(.text.double_sub_same_sign))                        /* 0x08045ba4 */
    KEEP(*(.text.float_to_double))                             /* 0x08045d70 */
    KEEP(*(.text.double_eq))                                   /* 0x08045dc6 */
    KEEP(*(.text.double_ne))                                   /* 0x08045dd4 */
    KEEP(*(.text.double_gt))                                   /* 0x08045de2 */
    KEEP(*(.text.double_ge))                                   /* 0x08045df0 */
    KEEP(*(.text.double_le))                                   /* 0x08045dfe */
    KEEP(*(.text.double_lt))                                   /* 0x08045e0c */
    KEEP(*(.text.u64_to_float))                                /* 0x08045e1a */
    KEEP(*(.text.i64_to_float))                                /* 0x08045e20 */
    KEEP(*(.text.uint64_to_float_core))                        /* 0x08045e34 */
    KEEP(*(.text.float_special_dispatch))                      /* 0x08045e7a */
    KEEP(*(.text.fpscr_set_fz_dn_round_nearest))               /* 0x08045f06 */
    KEEP(*(.text.float_ieee_remainder))                        /* 0x08045f20, with float_remainder_special_case 0x08045ff6 */
    KEEP(*(.text.double_to_i64))                               /* 0x08046020 */
    KEEP(*(.text.double_to_u64))                               /* 0x080460e4 */
    KEEP(*(.text.double_to_u64_special_case))                  /* 0x08046146 */
    KEEP(*(.text.double_scale_by_pow2))                        /* 0x080461c8 */
  } > FLASH
  .rodata :                                                        /* data, right after the code */
  {
    KEEP(*(.rodata.fixed))                                         /* src/rodata.s */
    KEEP(*(.rodata.ram_init))                                      /* src/ram_init.s: initial RAM image, word aligned */
  } > FLASH
  .text_added :                                                    /* code added by this rewrite, right after the data */
  {
    KEEP(*(.text.copy_words))                                      /* scatter-load region 1 handler, src/startup_56.s */
    KEEP(*(.text.boot_dump))
    KEEP(*(.text.boot_install))
    KEEP(*(.text.usb_ctl))                                         /* USB control channel */
    KEEP(*(.rodata.boot_install))                                  /* starter and slot images */
    app_image_end = .;
  } > FLASH
  /DISCARD/ : { *(.ARM.attributes) *(.comment) *(.ARM.exidx*) }
}
